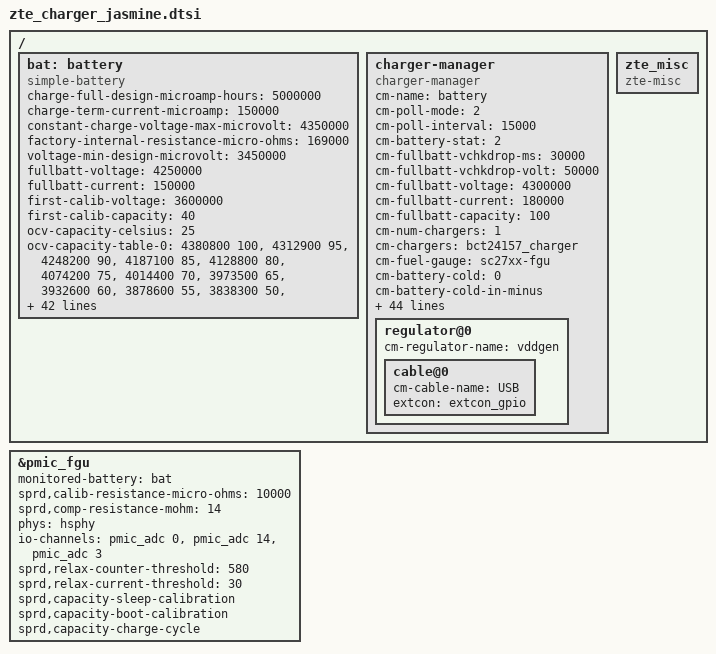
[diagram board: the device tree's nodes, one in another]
/ {
	bat: battery {
		compatible = "simple-battery";
		charge-full-design-microamp-hours = <2780000>;
		charge-term-current-microamp = <120000>;
		constant-charge-voltage-max-microvolt = <4350000>;
		factory-internal-resistance-micro-ohms = <320000>;
		voltage-min-design-microvolt = <3450000>;
		fullbatt-voltage = <4350000>;
		fullbatt-current = <120000>;
		first-calib-voltage = <3630000>;
		first-calib-capacity = <50>;

		ocv-capacity-celsius = <20>;
		ocv-capacity-table-0 = <4330000 100>, <4249000 95>, <4189000 90>,
					<4133000 85>, <4081000 80>, <4034000 75>,
					<3991000 70>, <3953000 65>, <3910000 60>,
					<3866000 55>, <3836000 50>, <3813000 45>,
					<3795000 40>, <3782000 35>, <3774000 30>,
					<3765000 25>, <3750000 20>, <3726000 15>,
					<3687000 10>, <3658000 5>, <3400000 0>;
		voltage-temp-table = <1095000 800>, <986000 850>, <878000 900>,
					  <775000 950>, <678000 1000>, <590000 1050>,
					  <510000 1100>, <440000 1150>, <378000 1200>,
					  <324000 1250>, <278000 1300>, <238000 1350>,
					  <204000 1400>, <175000 1450>, <150000 1500>,
					  <129000 1550>, <111000 1600>, <96000 1650>;
		capacity-temp-table = <25 100>, <10 97>, <(-10) 60>;
		resistance-temp-table = <20 100>, <10 243>, <(-10) 468>;
		charge-sdp-current-microamp = <500000 500000>;
		charge-dcp-current-microamp = <1150000 3000000>;
		charge-cdp-current-microamp = <1150000 1150000>;
		charge-unknown-current-microamp = <500000 500000>;

		dcp-jeita-temp-table = <1000 1030 0 4400000>, <1150 1180 700000 4400000>,
			<1450 1420 1150000 4400000>, <1600 1570 700000 4100000>;
		sdp-jeita-temp-table = <1000 1030 0 4400000>, <1150 1180 500000 4400000>,
			<1450 1420 500000 4400000>, <1600 1570 500000 4100000>;
		cdp-jeita-temp-table = <1000 1030 0 4400000>, <1150 1180 700000 4400000>,
			<1450 1420 1150000 4400000>, <1600 1570 700000 4100000>;
		unknown-jeita-temp-table = <1000 1030 0 4400000>, <1150 1180 500000 4400000>,
			<1450 1420 500000 4400000>, <1600 1570 500000 4100000>;
		force-jeita-status = <2>;
	};

	charger-manager {
		compatible = "charger-manager";
		cm-name = "battery";
		cm-poll-mode = <2>;
		cm-poll-interval = <15000>;
		cm-battery-stat = <2>;

		cm-fullbatt-vchkdrop-ms = <30000>;
		cm-fullbatt-vchkdrop-volt = <60000>;
		cm-fullbatt-voltage = <4320000>;
		cm-fullbatt-current = <120000>;
		cm-fullbatt-capacity = <100>;

		cm-num-chargers = <1>;
		cm-chargers = "sc2721_charger";
		cm-fuel-gauge = "sc27xx-fgu";

		/* in deci centigrade */
		cm-battery-cold = <200>;
		cm-battery-cold-in-minus;
		cm-battery-hot = <800>;
		cm-battery-temp-diff = <100>;

		/* Allow charging for 6hr */
		cm-charging-max = <18000000>;
		/* recovery charging after stop charging 45min */
		cm-discharging-max = <2700000>;

		/* the interval to feed charger watchdog */
		cm-wdt-interval = <60>;

		/* drop voltage in microVolts to allow shutdown */
		cm-shutdown-voltage = <3100000>;

		/* when 99% of the time is exceeded, it will be forced to 100% */
		cm-tickle-time-out = <1500>;

		/* how much time to allow capacity change */
		cm-one-cap-time = <30>;

		/* when the safe charging voltage is exceeded, stop charging */
		cm-charge-voltage-max = <6500000>;
		/* drop voltage in microVolts to restart charging */
		cm-charge-voltage-drop = <700000>;
		cm-dcp-jeita-temp-table = <1000 1030 0 4350000>, <1150 1180 700000 4350000>,
			<1450 1420 1150000 4350000>, <1600 1570 700000 4100000>;
		cm-sdp-jeita-temp-table = <1000 1030 0 4350000>, <1150 1180 500000 4350000>,
			<1450 1420 500000 4350000>, <1600 1570 500000 4100000>;
		cm-cdp-jeita-temp-table = <1000 1030 0 4350000>, <1150 1180 700000 4350000>,
			<1450 1420 1150000 4350000>, <1600 1570 700000 4100000>;
		cm-unknown-jeita-temp-table = <1000 1030 0 4350000>, <1150 1180 500000 4350000>,
			<1450 1420 500000 4350000>, <1600 1570 500000 4100000>;

		monitored-battery = <&bat>;
		cm-capacity-track;

		regulator@0 {
			cm-regulator-name = "vddgen";
			cable@0 {
				cm-cable-name = "USB";
				extcon = <&extcon_gpio>;
			};
		};
	};
};

&bat {
	charge-full-design-microamp-hours = <5000000>;
	charge-full-microamp-hours = <4750000>;
	charge-term-current-microamp = <150000>;
	constant-charge-voltage-max-microvolt = <4350000>;
	constant-charge-current-max-microamp = <1000000>;
	factory-internal-resistance-micro-ohms = <169000>;
	voltage-min-design-microvolt = <3450000>;
	fullbatt-advance-level = <980>;
	fullbatt-voltage = <4250000>;
	fullbatt-current = <150000>;
	first-calib-voltage = <3600000>;
	first-calib-capacity = <40>;
	ocv-capacity-celsius = <25>;
	/*
	batt-id-list = <47 330>;
	*/
	ocv-capacity-table-0 = <4380800 100>, <4312900 95>, <4248200 90>,
				<4187100 85>, <4128800 80>, <4074200 75>,
				<4014400 70>, <3973500 65>, <3932600 60>,
				<3878600 55>, <3838300 50>, <3813500 45>,
				<3795200 40>, <3781900 35>, <3776300 30>,
				<3766100 25>, <3749000 20>, <3728200 15>,
				<3689800 10>, <3604200 5>, <3371700 0>;
	/* NTC 47k, data from sprd original */
	voltage-temp-table = <1110270 800>, <999440 850>, <890430 900>,
				<785590 950>, <687630 1000>, <598220 1050>,
				<517680 1100>, <446100 1150>, <383390 1200>,
				<328950 1250>, <281840 1300>, <241480 1350>,
				<207030 1400>, <177580 1450>, <152490 1500>,
				<131160 1550>, <113000 1600>, <97790 1650>;
	charge-sdp-current-microamp = <500000 500000>;
	charge-dcp-current-microamp = <1000000 1000000>;
	charge-cdp-current-microamp = <1000000 1000000>;
	charge-unknown-current-microamp = <500000 500000>;
	capacity-temp-table = <50 100>, <25 100>, <10 98>, <0 93>, <(-10) 71>;
	resistance-temp-table = <50 124>, <25 169>, <10 338>, <0 626>, <(-10) 1298>;
	dcp-jeita-temp-table = <1000 1030 0 4400000>,
				<1050 1080 800000 4400000>,
				<1150 1180 800000 4400000>,
				<1450 1420 1000000 4400000>,
				<1550 1520 800000 4100000>;
	sdp-jeita-temp-table = <1000 1030 0 4400000>,
				<1050 1080 500000 4400000>,
				<1150 1180 500000 4400000>,
				<1450 1420 500000 4400000>,
				<1550 1520 500000 4100000>;
	cdp-jeita-temp-table = <1000 1030 0 4400000>,
				<1050 1080 800000 4400000>,
				<1150 1180 800000 4400000>,
				<1450 1420 1000000 4400000>,
				<1550 1520 800000 4100000>;
	unknown-jeita-temp-table = <1000 1030 0 4400000>,
				<1050 1080 500000 4400000>,
				<1150 1180 500000 4400000>,
				<1450 1420 500000 4400000>,
				<1550 1520 500000 4100000>;
};

&pmic_fgu {
	monitored-battery = <&bat>;
	sprd,calib-resistance-micro-ohms = <10000>;
	sprd,comp-resistance-mohm = <14>;

	phys = <&hsphy>;
	io-channels = <&pmic_adc 0>, <&pmic_adc 14>, <&pmic_adc 3>;
	io-channel-names = "bat-temp", "charge-vol", "adc-batt-id";

	sprd,relax-counter-threshold = <580>;
	sprd,relax-current-threshold = <30>;
	sprd,capacity-sleep-calibration;

	sprd,capacity-boot-calibration;
	sprd,capacity-charge-cycle;
};

/ {
	charger-manager {
		cm-fullbatt-voltage = <4300000>;
		cm-fullbatt-vchkdrop-volt = <50000>;
		cm-fullbatt-current = <180000>;
		cm-fullbatt-comp-voltage = <32000>;
		cm-thermal-limit = <2>;
		/* in deci centigrade */
		cm-battery-cold = <0>;
		cm-battery-hot = <550>;
		cm-battery-temp-diff = <30>;
		cm-tickle-time-out = <180>;
		cm-charge-voltage-max = <5900000>;
		cm-charge-voltage-drop = <500000>;

		cm-disable-charger-type-jeita;
		cm-jeita-temp-table = <1000 1030 0 4350000>,
				<1050 1080 600000 4350000>,
				<1150 1180 600000 4350000>,
				<1450 1420 1000000 4350000>,
				<1550 1520 900000 4100000>;
		charge-sdp-current-microamp = <700000 500000>;
		charge-dcp-current-microamp = <1000000 1000000>;
		charge-cdp-current-microamp = <1000000 1000000>;
		charge-unknown-current-microamp = <1000000 1000000>;

		cm-chargers = "bct24157_charger";
		cm-hardware-psy = "bct24157_charger";
		monitored-battery =<&bat>;
		phys = <&hsphy>;
	};

	zte_misc: zte_misc {
		status = "okay";
		compatible = "zte-misc";
	};
};

#include "../bat_setting/battery_protect_policy_080500100347.dtsi"
